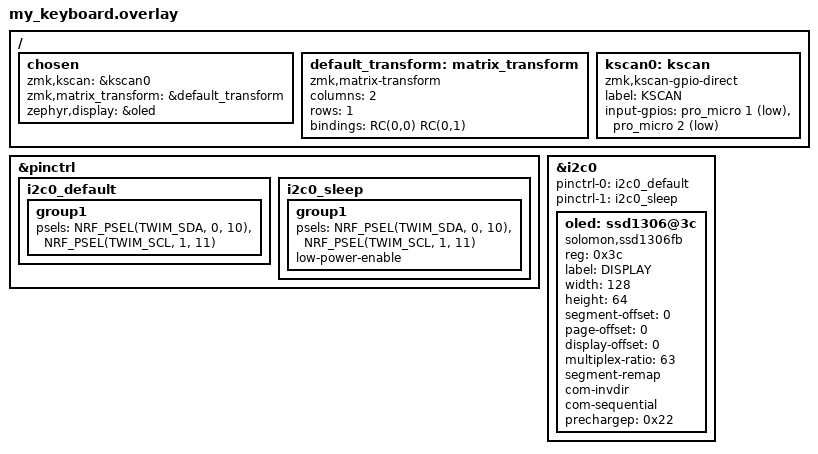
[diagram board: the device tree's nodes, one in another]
#include <dt-bindings/zmk/matrix_transform.h>

/ {
    chosen {
        zmk,kscan = &kscan0;
        zmk,matrix_transform = &default_transform;
        zephyr,display = &oled;
    };

    default_transform: matrix_transform {
        compatible = "zmk,matrix-transform";
        columns = <2>;
        rows = <1>;
        bindings = <
            RC(0,0) RC(0,1)
        >;
    };

    kscan0: kscan {
        compatible = "zmk,kscan-gpio-direct";
        label = "KSCAN";
        input-gpios
            = <&pro_micro 1 (GPIO_ACTIVE_LOW | GPIO_PULL_UP)>
            , <&pro_micro 2 (GPIO_ACTIVE_LOW | GPIO_PULL_UP)>
            ;
    };
};

&pinctrl {
    i2c0_default: i2c0_default {
        group1 {
            /* SDA on P0.10, SCL on P1.11 */
            psels = <NRF_PSEL(TWIM_SDA, 0, 10)>,
                    <NRF_PSEL(TWIM_SCL, 1, 11)>;
        };
    };

    i2c0_sleep: i2c0_sleep {
        group1 {
            psels = <NRF_PSEL(TWIM_SDA, 0, 10)>,
                    <NRF_PSEL(TWIM_SCL, 1, 11)>;
            low-power-enable;
        };
    };
};

&i2c0 {
    status = "okay";
    pinctrl-0 = <&i2c0_default>;
    pinctrl-1 = <&i2c0_sleep>;
    pinctrl-names = "default", "sleep";

    oled: ssd1306@3c {
        compatible = "solomon,ssd1306fb";
        reg = <0x3c>;
        label = "DISPLAY";
        width = <128>;
        height = <64>;
        segment-offset = <0>;
        page-offset = <0>;
        display-offset = <0>;
        multiplex-ratio = <63>;
        segment-remap;
        com-invdir;
        com-sequential;
        prechargep = <0x22>;
    };
};
